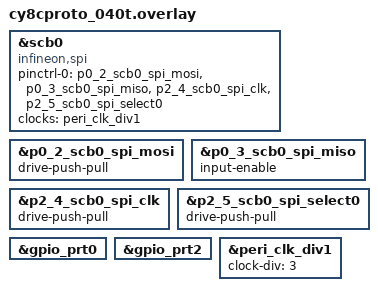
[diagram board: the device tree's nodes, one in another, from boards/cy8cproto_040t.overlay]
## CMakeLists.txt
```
# SPDX-License-Identifier: Apache-2.0

cmake_minimum_required(VERSION 3.28.0)
find_package(Zephyr REQUIRED HINTS $ENV{ZEPHYR_BASE})
project(spi_psoc4)

FILE(GLOB app_sources src/*.c)
target_sources(app PRIVATE ${app_sources})
```

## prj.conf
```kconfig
# SCB0 is the console UART on this board; it is repurposed as SPI master
# here, so no UART/console is available in this sample.
CONFIG_SPI=y
CONFIG_GPIO=y
```

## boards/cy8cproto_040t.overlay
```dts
/*
 * SPDX-FileCopyrightText: <text>Copyright (c) 2026 Infineon Technologies AG,
 * or an affiliate of Infineon Technologies AG. All rights reserved.</text>
 *
 * SPDX-License-Identifier: Apache-2.0
 */

#include <zephyr/dt-bindings/gpio/gpio.h>

/* SCB0 is the only SPI-capable SCB on this package, so the hardware UART
 * console on SCB0 is disabled in favor of SPI master mode. This sample has
 * no console; verify operation with a logic analyzer and by watching the
 * slave board's LED toggle.
 *
 * Logic-analyzer probe points:
 *   MOSI -> P0.2
 *   MISO -> P0.3
 *   SCLK -> P2.4
 *   CS   -> P2.5 (SCB hardware slave-select SS0, active low)
 *
 * NOTE: P1.0 is NOT used for CS even though it's a free GPIO on paper --
 * it is also wired to the onboard LED2/button SW4 circuit, multiplexed by
 * jumper J6, so an external wire to "P1.0" may not reliably reach the MCU
 * pin depending on J6's position.
 */

uart0: &scb0 {
	status = "disabled";
};

spi1: &scb0 {
	compatible = "infineon,spi";
	status = "okay";
	/delete-property/ current-speed;
	pinctrl-0 = <&p0_2_scb0_spi_mosi &p0_3_scb0_spi_miso
		     &p2_4_scb0_spi_clk &p2_5_scb0_spi_select0>;
	pinctrl-names = "default";
	clocks = <&peri_clk_div1>;
	#address-cells = <1>;
	#size-cells = <0>;
};

&p0_2_scb0_spi_mosi {
	drive-push-pull;
};

&p0_3_scb0_spi_miso {
	input-enable;
};

&p2_4_scb0_spi_clk {
	drive-push-pull;
};

&p2_5_scb0_spi_select0 {
	drive-push-pull;
};

&gpio_prt0 {
	status = "okay";
};

&gpio_prt2 {
	status = "okay";
};

&peri_clk_div1 {
	status = "okay";
    clock-div = <3>;
};
```

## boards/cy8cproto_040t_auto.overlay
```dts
/*
 * SPDX-FileCopyrightText: <text>Copyright (c) 2026 Infineon Technologies AG,
 * or an affiliate of Infineon Technologies AG. All rights reserved.</text>
 *
 * SPDX-License-Identifier: Apache-2.0
 */

#include <zephyr/dt-bindings/gpio/gpio.h>

/* SCB0 is the only SPI-capable SCB on this package, so the hardware UART
 * console on SCB0 is disabled in favor of SPI master mode. This sample has
 * no console; verify operation with a logic analyzer and by watching the
 * slave board's LED toggle.
 *
 * Logic-analyzer probe points:
 *   MOSI -> P0.2
 *   MISO -> P0.3
 *   SCLK -> P2.4
 *   CS   -> P2.5 (SCB hardware slave-select SS0, active low)
 */

uart0: &scb0 {
	status = "disabled";
};

spi1: &scb0 {
	compatible = "infineon,spi";
	status = "okay";
	/delete-property/ current-speed;
	pinctrl-0 = <&p0_2_scb0_spi_mosi &p0_3_scb0_spi_miso
		     &p2_4_scb0_spi_clk &p2_5_scb0_spi_select0>;
	pinctrl-names = "default";
	clocks = <&peri_clk_div1>;
	#address-cells = <1>;
	#size-cells = <0>;
};

&p0_2_scb0_spi_mosi {
	drive-push-pull;
};

&p0_3_scb0_spi_miso {
	input-enable;
};

&p2_4_scb0_spi_clk {
	drive-push-pull;
};

&p2_5_scb0_spi_select0 {
	drive-push-pull;
};

&gpio_prt0 {
	status = "okay";
};

&gpio_prt2 {
	status = "okay";
};

&peri_clk_div1 {
	status = "okay";
	clock-div = <3>;
};
```

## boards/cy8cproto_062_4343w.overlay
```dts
/*
 * SPDX-FileCopyrightText: <text>Copyright (c) 2026 Infineon Technologies AG,
 * or an affiliate of Infineon Technologies AG. All rights reserved.</text>
 *
 * SPDX-License-Identifier: Apache-2.0
 */

/* This board is PSOC6/CAT1A: ifx_cat1_spi_transfer_async() takes the
 * Cy_SCB_SPI_Transfer_Buffer() path (IFX_SPI_ASYMM_PDL_FUNC_AVAIL), not the
 * PSOC4 manual-chunking path the original bug was found in. This overlay
 * lets the same sample check whether the slave-role problem also shows up
 * on that different driver path.
 *
 * SCB3 has no pre-generated SPI pinctrl nodes (only I2C/UART), so its pins
 * are hand-defined below. SCB3 doubles as the board's default I2C bus
 * (i2c3); this overlay repurposes it for SPI master mode instead.
 *
 * Logic-analyzer probe points:
 *   MOSI -> P6.0
 *   MISO -> P6.1
 *   SCLK -> P6.2
 *   CS   -> P6.3 (SCB hardware slave-select SS0, active low)
 */

spi1: &scb3 {
	compatible = "infineon,spi";
	status = "okay";

	pinctrl-0 = <&p6_0_scb3_spi_m_mosi &p6_1_scb3_spi_m_miso
		     &p6_2_scb3_spi_m_clk &p6_3_scb3_spi_m_select0>;
	pinctrl-names = "default";
};

&pinctrl {
	p6_0_scb3_spi_m_mosi: p6_0_scb3_spi_m_mosi {
		pinmux = <DT_CAT1_PINMUX(6, 0, HSIOM_SEL_ACT_8)>;
		drive-push-pull;
	};

	p6_1_scb3_spi_m_miso: p6_1_scb3_spi_m_miso {
		pinmux = <DT_CAT1_PINMUX(6, 1, HSIOM_SEL_ACT_8)>;
		input-enable;
	};

	p6_2_scb3_spi_m_clk: p6_2_scb3_spi_m_clk {
		pinmux = <DT_CAT1_PINMUX(6, 2, HSIOM_SEL_ACT_8)>;
		drive-push-pull;
	};

	p6_3_scb3_spi_m_select0: p6_3_scb3_spi_m_select0 {
		pinmux = <DT_CAT1_PINMUX(6, 3, HSIOM_SEL_ACT_8)>;
		drive-push-pull;
	};
};
```

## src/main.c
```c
/*
 * SPDX-FileCopyrightText: <text>Copyright (c) 2026 Infineon Technologies AG,
 * or an affiliate of Infineon Technologies AG. All rights reserved.</text>
 *
 * SPDX-License-Identifier: Apache-2.0
 */

#include <zephyr/kernel.h>
#include <zephyr/device.h>
#include <zephyr/devicetree.h>
#include <zephyr/drivers/spi.h>

#define SPI_NODE DT_NODELABEL(spi1)

/* 3-byte framed protocol: SOP, command, EOP. The slave validates the frame
 * markers before acting on the command byte.
 */
#define PACKET_SOP_POS 0
#define PACKET_CMD_POS 1
#define PACKET_EOP_POS 2
#define PACKET_SOP     0x01U
#define PACKET_EOP     0x17U

#define LED_STATE_ON  0x01U
#define LED_STATE_OFF 0x00U

static const struct device *const spi_dev = DEVICE_DT_GET(SPI_NODE);

/* CS is driven by the SCB's hardware slave-select (SS0), so it is asserted
 * automatically for exactly the transfer duration -- no GPIO cs entry.
 */
static const struct spi_config spi_cfg = {
	.frequency = 1000000,
	.operation = SPI_OP_MODE_CONTROLLER | SPI_WORD_SET(8) | SPI_TRANSFER_MSB,
	.slave = 0,
};

int main(void)
{
	if (!device_is_ready(spi_dev)) {
		return 0;
	}

	uint8_t led_cmd = LED_STATE_OFF;

	while (1) {
		led_cmd = (led_cmd == LED_STATE_OFF) ? LED_STATE_ON : LED_STATE_OFF;

		uint8_t tx_data[3];

		tx_data[PACKET_SOP_POS] = PACKET_SOP;
		tx_data[PACKET_CMD_POS] = led_cmd;
		tx_data[PACKET_EOP_POS] = PACKET_EOP;

		const struct spi_buf tx_buf = {.buf = tx_data, .len = sizeof(tx_data)};
		const struct spi_buf_set tx_set = {.buffers = &tx_buf, .count = 1};

		spi_write(spi_dev, &spi_cfg, &tx_set);

		k_sleep(K_MSEC(1000));
	}

	return 0;
}
```
